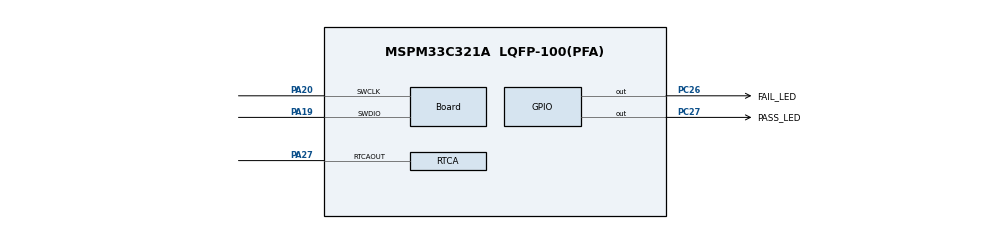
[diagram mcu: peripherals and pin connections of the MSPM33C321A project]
//@cliArgs --device "MSPM33C321A" --package "LQFP-100(PFA)" --part "Default"
//@v2CliArgs --device "MSPM33C321A" --package "LQFP-100(PFA)"
// @cliArgs --board /ti/boards/LP_MSPM33C321A --rtos nortos


/**
 * Import the modules used in this configuration.
 */
const GPIO   = scripting.addModule("/ti/driverlib/GPIO", {}, false);
const GPIO1  = GPIO.addInstance();
const RTCA   = scripting.addModule("/ti/driverlib/RTCA");
const SYSCTL = scripting.addModule("/ti/driverlib/SYSCTL");

/**
 * Write custom configuration values to the imported modules.
 */
GPIO1.$name                               = "GPIO_LEDS";
GPIO1.associatedPins.create(2);
GPIO1.associatedPins[0].$name             = "PASS_LED";
GPIO1.associatedPins[0].launchPadShortcut = "LED2GreenEn";
GPIO1.associatedPins[0].pin.$assign       = "PC27";
GPIO1.associatedPins[1].$name             = "FAIL_LED";
GPIO1.associatedPins[1].launchPadShortcut = "LED2RedEn";
GPIO1.associatedPins[1].pin.$assign       = "PC26";

const Board                       = scripting.addModule("/ti/driverlib/Board", {}, false);
Board.peripheral.$assign          = "DEBUGSS";
Board.peripheral.swclkPin.$assign = "PA20";
Board.peripheral.swdioPin.$assign = "PA19";

RTCA.calSec                        = 59;
RTCA.calMin                        = 32;
RTCA.calHour                       = 10;
RTCA.calDOW                        = "1";
RTCA.calDOM                        = 5;
RTCA.calMonth                      = "4";
RTCA.calYear                       = 2021;
RTCA.enCalAlarm1                   = true;
RTCA.enCalAlarm1Min                = true;
RTCA.enCalAlarm1Hour               = true;
RTCA.enCalAlarm1DOW                = true;
RTCA.enCalAlarm1DOM                = true;
RTCA.calAlarm1Min                  = 33;
RTCA.calAlarm1Hour                 = 10;
RTCA.calAlarm1DOW                  = "1";
RTCA.calAlarm1DOM                  = 5;
RTCA.enabledInterrupts             = ["CALENDAR_ALARM1"];
RTCA.peripheral.$assign            = "LFSS";
RTCA.peripheral.rtcaOutPin.$assign = "PA27";

SYSCTL.powerPolicy        = "STANDBY0";
SYSCTL.peripheral.$assign = "SYSCTL";

const ProjectConfig              = scripting.addModule("/ti/project_config/ProjectConfig", {}, false);
ProjectConfig.migrationCondition = true;
